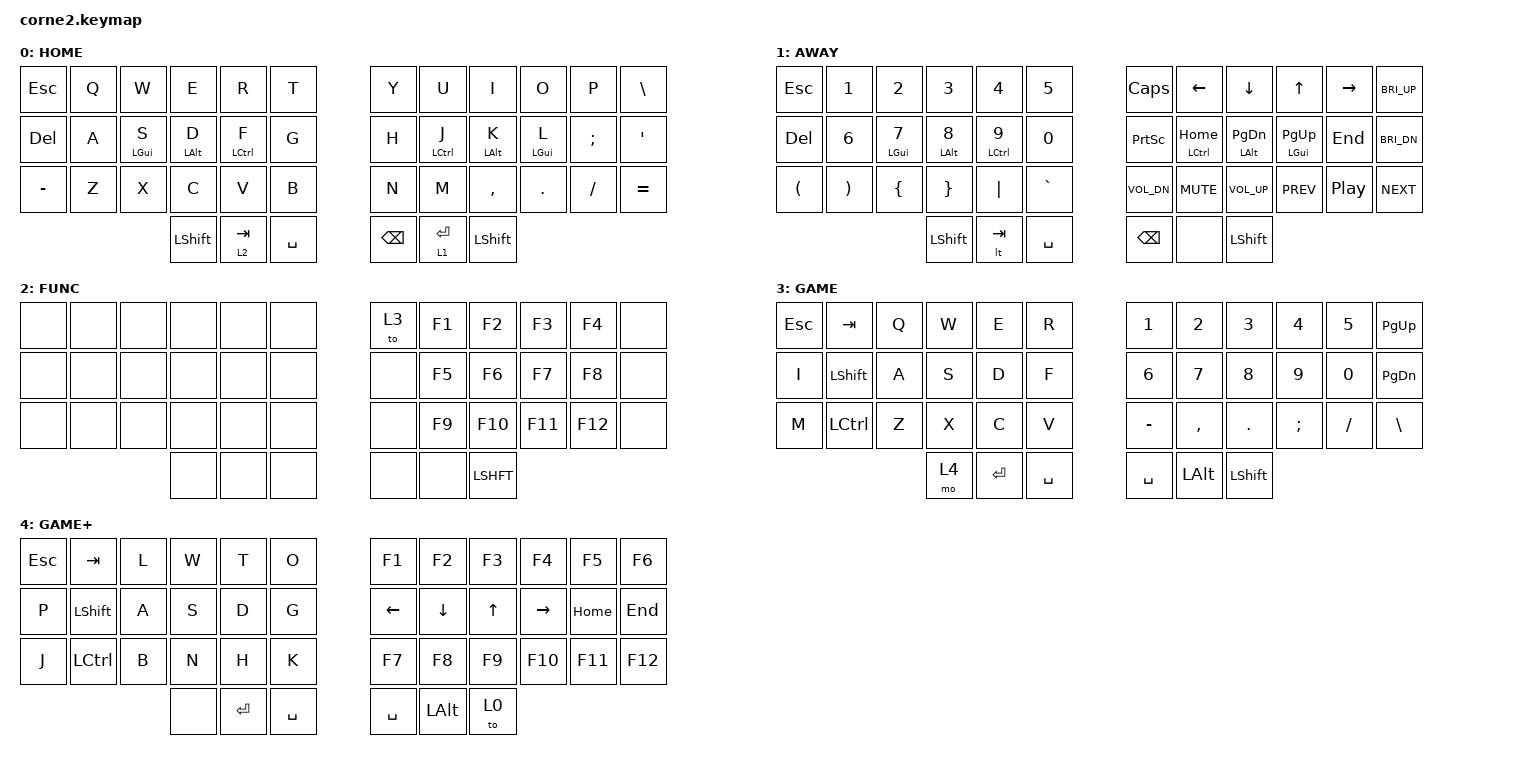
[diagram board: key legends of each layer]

#include <behaviors.dtsi>
#include <dt-bindings/zmk/keys.h>
#include <dt-bindings/zmk/bt.h>
#include <dt-bindings/zmk/ext_power.h>

&mt {
    tapping-term-ms = <200>;
    quick-tap-ms = <200>;
    require-prior-idle-ms=<125>;
    flavor = "balanced";
};

/ {
    keymap {
        compatible = "zmk,keymap";

        layer_0 {
            bindings = <
                &kp ESC     &kp Q       &kp W       &kp E       &kp R        &kp T        &kp Y     &kp U        &kp I        &kp O       &kp P          &kp BSLH
                &kp DEL     &kp A       &mt LGUI S  &mt LALT D  &mt LCTRL F  &kp G        &kp H     &mt LCTRL J  &mt LALT K   &mt LGUI L  &kp SEMICOLON  &kp SQT
                &kp MINUS   &kp Z       &kp X       &kp C       &kp V        &kp B        &kp N     &kp M        &kp COMMA    &kp DOT     &kp FSLH       &kp EQUAL
                                                    &kp LSHFT   &lt 2 TAB    &kp SPACE    &kp BSPC  &lt 1 ENTER  &kp LSHFT
            >;
            display-name = "HOME";
        };

        layer_1 {
            bindings = <
                &kp ESC     &kp N1      &kp N2      &kp N3      &kp N4       &kp N5       &kp CAPS  	&kp LEFT     	&kp DOWN     	&kp UP      	&kp RIGHT   		&kp C_BRI_UP
                &kp DEL     &kp N6      &mt LGUI N7 &mt LALT N8 &mt LCTRL N9 &kp N0       &kp PSCRN 	&mt LCTRL HOME  &mt LALT PG_DN  &mt LGUI PG_UP  &kp END  			&kp C_BRI_DN
                &kp LPAR    &kp RPAR    &kp LBRC    &kp RBRC    &kp PIPE     &kp GRAVE    &kp C_VOL_DN  &kp C_MUTE    	&kp C_VOL_UP    &kp C_PREV     	&kp C_PLAY_PAUSE    &kp C_NEXT
                                                    &kp LSHFT   &lt TAB      &kp SPACE    &kp BSPC  	&none   		&kp LSHFT
            >;
            display-name = "AWAY";
        };

        layer_2 {
            bindings = <
				&none  	&none   &none   &none   &none	&none    &to 3  		&kp F1    &kp F2	&kp F3		&kp F4		&none
				&none  	&none   &none   &none   &none	&none    &none  		&kp F5    &kp F6	&kp F7		&kp F8		&none
				&none  	&none   &none   &none   &none	&none    &none  		&kp F9    &kp F10	&kp F11		&kp F12		&none
												&none   &none	 &none          &none     &none  	&LSHFT
            >;
            display-name="FUNC";
        };

		layer_3 {
			bindings = <
				&kp ESC	&kp TAB		&kp Q	&kp W	&kp E 		&kp R		&kp N1		&kp N2		&kp N3	&kp N4			&kp N5		&kp PG_UP
				&kp I	&kp LSHFT	&kp A	&kp S	&kp D 		&kp F		&kp N6		&kp N7		&kp N8	&kp N9			&kp N0		&kp PG_DN
				&kp M	&kp LCTRL	&kp Z	&kp X	&kp C 		&kp V		&kp MINUS	&kp COMMA	&kp DOT	&kp SEMICOLON	&kp SLASH	&kp BSLH
											&mo 4	&kp ENTER	&kp SPACE	&kp SPACE	&kp LALT	&kp LSHFT
			>;
			display-name = "GAME";
		};

		layer_4 {
			bindings = <
				&kp ESC	&kp TAB		&kp L	&kp W	&kp T 		&kp O		&kp F1		&kp F2		&kp F3	&kp F4		&kp F5		&kp F6
				&kp P	&kp LSHFT	&kp A	&kp S	&kp D 		&kp G		&kp LEFT	&kp DOWN	&kp UP	&kp RIGHT	&kp HOME	&kp END
				&kp J	&kp LCTRL	&kp B	&kp N	&kp H 		&kp K		&kp F7		&kp F8		&kp F9	&kp F10		&kp F11		&kp F12
											&none	&kp ENTER	&kp SPACE	&kp SPACE	&kp LALT	&to 0
			>;
			display-name = "GAME+";
		};

	};
};
